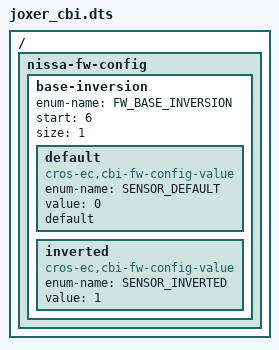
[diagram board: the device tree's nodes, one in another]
/* Copyright 2022 The Chromium OS Authors. All rights reserved.
 * Use of this source code is governed by a BSD-style license that can be
 * found in the LICENSE file.
 */

/ {
  /* Joxer-specific fw_config fields. */
	nissa-fw-config {
		/*
		 * FW_CONFIG field to describe mainboard orientation in chassis.
		 */
		base-inversion {
			enum-name = "FW_BASE_INVERSION";
			start = <6>;
			size = <1>;

			default {
				compatible = "cros-ec,cbi-fw-config-value";
				enum-name = "SENSOR_DEFAULT";
				value = <0>;
				default;
			};
			inverted {
				compatible = "cros-ec,cbi-fw-config-value";
				enum-name = "SENSOR_INVERTED";
				value = <1>;
			};
		};
	};
};
